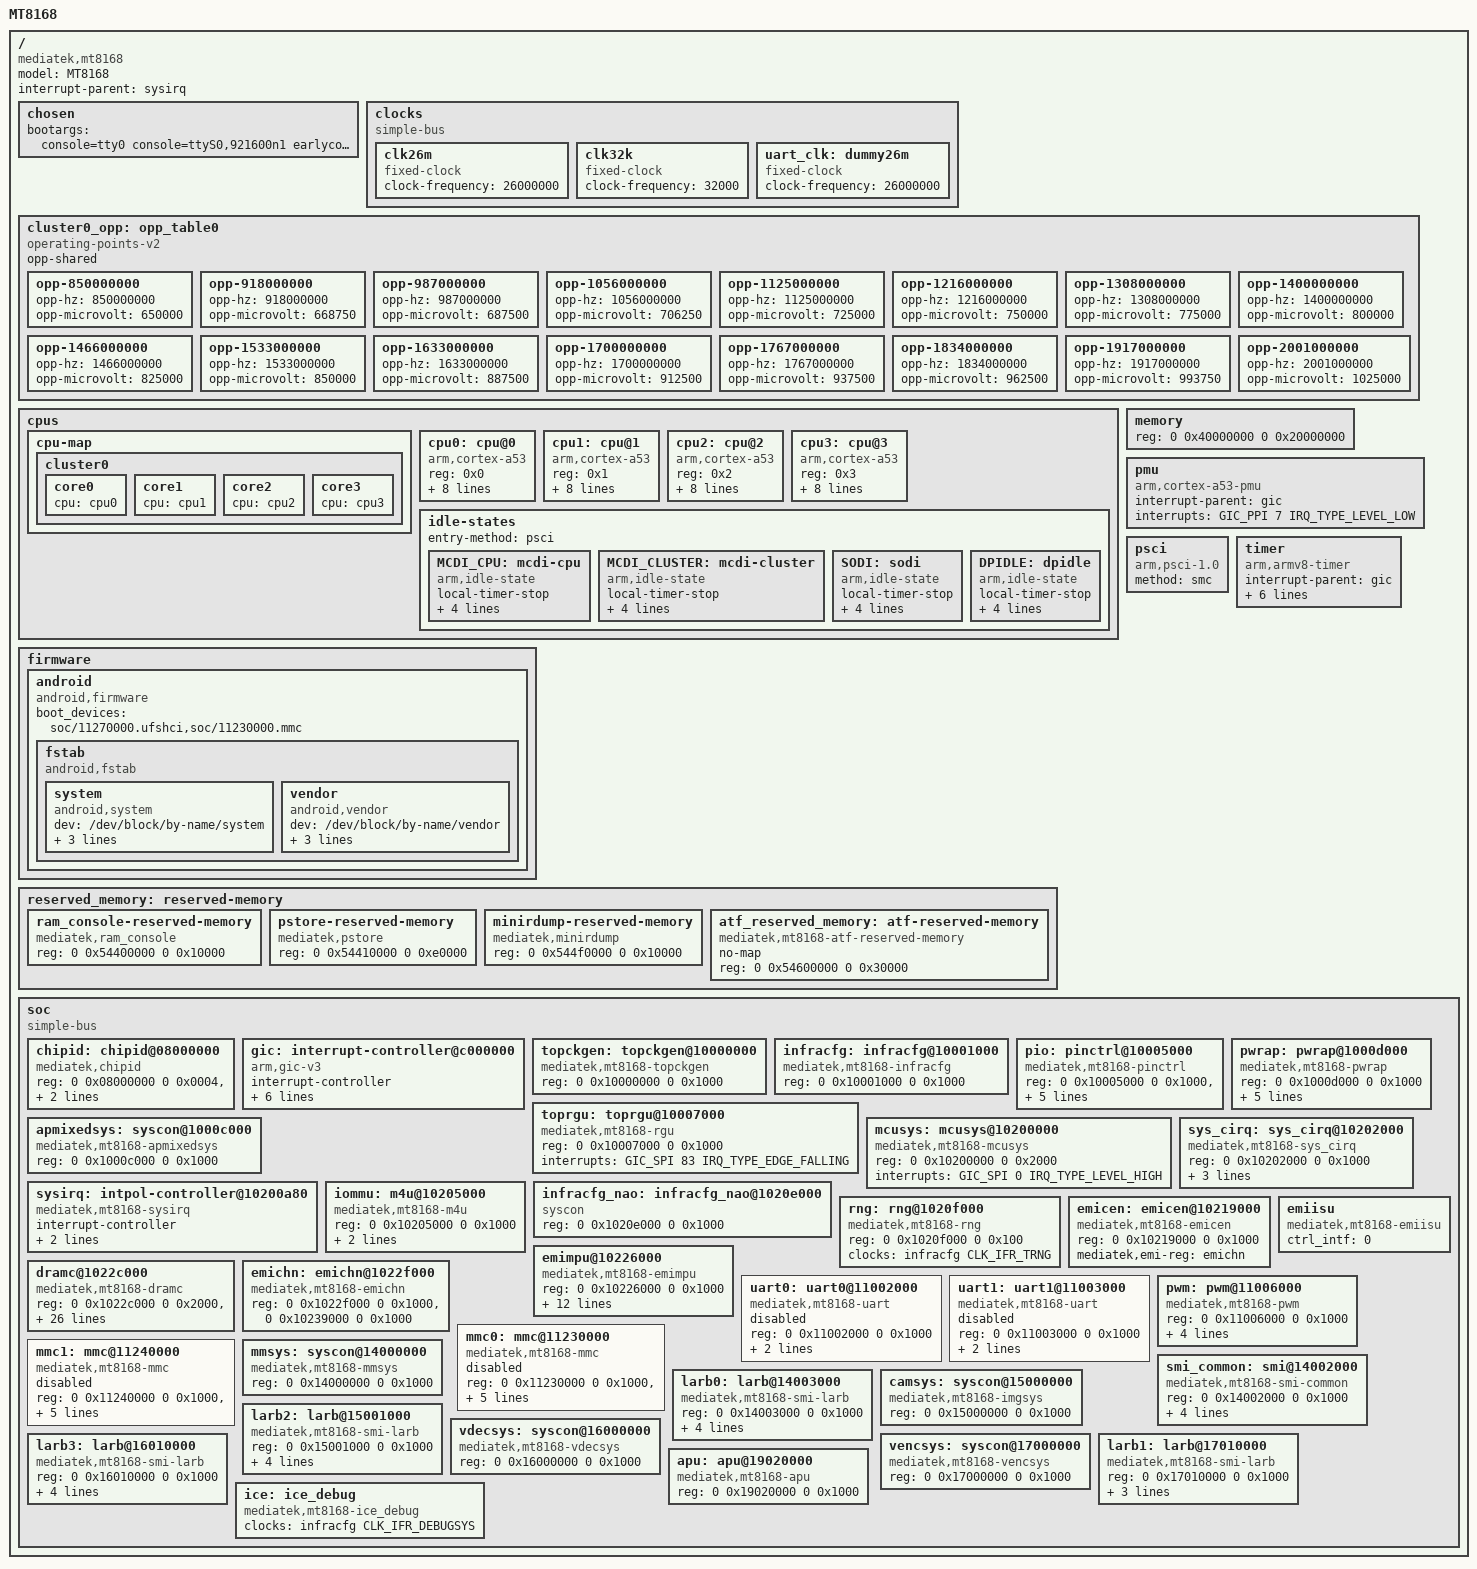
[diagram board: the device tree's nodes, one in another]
// SPDX-License-Identifier: GPL-2.0
/*
 * Mediatek's MT8168 SoC device tree source
 * Copyright (c) 2019 MediaTek Inc.
 */

#include <dt-bindings/clock/mt8168-clk.h>
#include <dt-bindings/iio/mt635x-auxadc.h>
#include <dt-bindings/interrupt-controller/irq.h>
#include <dt-bindings/interrupt-controller/arm-gic.h>
#include <dt-bindings/memory/mt8168-larb-port.h>
#include <dt-bindings/phy/phy.h>
#include <dt-bindings/pinctrl/mt8168-pinfunc.h>

/ {
	model = "MT8168";
	compatible = "mediatek,mt8168";
	interrupt-parent = <&sysirq>;
	#address-cells = <2>;
	#size-cells = <2>;

	/* chosen */
	chosen: chosen {
		bootargs = "console=tty0 console=ttyS0,921600n1 earlycon=uart8250,mmio32,0x11002000 vmalloc=496M androidboot.hardware=mt8168 firmware_class.path=/vendor/firmware loop.max_part=7";
	};

	clocks {
		#address-cells = <2>;
		#size-cells = <2>;
		compatible = "simple-bus";
		ranges;

		clk26m: clk26m {
			compatible = "fixed-clock";
			#clock-cells = <0>;
			clock-frequency = <26000000>;
		};

		clk32k: clk32k {
			compatible = "fixed-clock";
			#clock-cells = <0>;
			clock-frequency = <32000>;
		};

		uart_clk: dummy26m {
			compatible = "fixed-clock";
			clock-frequency = <26000000>;
			#clock-cells = <0>;
		};
	};

	cluster0_opp: opp_table0 {
		compatible = "operating-points-v2";
		opp-shared;
		opp-850000000 {
			opp-hz = /bits/ 64 <850000000>;
			opp-microvolt = <650000>;
		};
		opp-918000000 {
			opp-hz = /bits/ 64 <918000000>;
			opp-microvolt = <668750>;
		};
		opp-987000000 {
			opp-hz = /bits/ 64 <987000000>;
			opp-microvolt = <687500>;
		};
		opp-1056000000 {
			opp-hz = /bits/ 64 <1056000000>;
			opp-microvolt = <706250>;
		};
		opp-1125000000 {
			opp-hz = /bits/ 64 <1125000000>;
			opp-microvolt = <725000>;
		};
		opp-1216000000 {
			opp-hz = /bits/ 64 <1216000000>;
			opp-microvolt = <750000>;
		};
		opp-1308000000 {
			opp-hz = /bits/ 64 <1308000000>;
			opp-microvolt = <775000>;
		};
		opp-1400000000 {
			opp-hz = /bits/ 64 <1400000000>;
			opp-microvolt = <800000>;
		};
		opp-1466000000 {
			opp-hz = /bits/ 64 <1466000000>;
			opp-microvolt = <825000>;
		};
		opp-1533000000 {
			opp-hz = /bits/ 64 <1533000000>;
			opp-microvolt = <850000>;
		};
		opp-1633000000 {
			opp-hz = /bits/ 64 <1633000000>;
			opp-microvolt = <887500>;
		};
		opp-1700000000 {
			opp-hz = /bits/ 64 <1700000000>;
			opp-microvolt = <912500>;
		};
		opp-1767000000 {
			opp-hz = /bits/ 64 <1767000000>;
			opp-microvolt = <937500>;
		};
		opp-1834000000 {
			opp-hz = /bits/ 64 <1834000000>;
			opp-microvolt = <962500>;
		};
		opp-1917000000 {
			opp-hz = /bits/ 64 <1917000000>;
			opp-microvolt = <993750>;
		};
		opp-2001000000 {
			opp-hz = /bits/ 64 <2001000000>;
			opp-microvolt = <1025000>;
		};
	};

	cpus: cpus {
		#address-cells = <1>;
		#size-cells = <0>;

		cpu-map {
			cluster0: cluster0 {
				core0 {
					cpu = <&cpu0>;
				};
				core1 {
					cpu = <&cpu1>;
				};
				core2 {
					cpu = <&cpu2>;
				};
				core3 {
					cpu = <&cpu3>;
				};
			};
		};

		cpu0: cpu@0 {
			device_type = "cpu";
			compatible = "arm,cortex-a53";
			reg = <0x0>;
			clock-frequency = <1600000000>;
			enable-method = "psci";
			cpu-idle-states = <&MCDI_CPU &MCDI_CLUSTER &SODI
					   &DPIDLE>;
			clocks = <&mcusys CLK_MCU_BUS_SEL>,
				 <&apmixedsys CLK_APMIXED_MAINPLL>,
				 <&apmixedsys CLK_APMIXED_ARMPLL>;
			clock-names = "cpu", "intermediate", "armpll";
			operating-points-v2 = <&cluster0_opp>;
		};

		cpu1: cpu@1 {
			device_type = "cpu";
			compatible = "arm,cortex-a53";
			reg = <0x1>;
			clock-frequency = <1600000000>;
			enable-method = "psci";
			cpu-idle-states = <&MCDI_CPU &MCDI_CLUSTER &SODI
					   &DPIDLE>;
			clocks = <&mcusys CLK_MCU_BUS_SEL>,
				 <&apmixedsys CLK_APMIXED_MAINPLL>,
				 <&apmixedsys CLK_APMIXED_ARMPLL>;
			clock-names = "cpu", "intermediate", "armpll";
			operating-points-v2 = <&cluster0_opp>;
		};

		cpu2: cpu@2 {
			device_type = "cpu";
			compatible = "arm,cortex-a53";
			reg = <0x2>;
			clock-frequency = <1600000000>;
			enable-method = "psci";
			cpu-idle-states = <&MCDI_CPU &MCDI_CLUSTER &SODI
					   &DPIDLE>;
			clocks = <&mcusys CLK_MCU_BUS_SEL>,
				 <&apmixedsys CLK_APMIXED_MAINPLL>,
				 <&apmixedsys CLK_APMIXED_ARMPLL>;
			clock-names = "cpu", "intermediate", "armpll";
			operating-points-v2 = <&cluster0_opp>;
		};

		cpu3: cpu@3 {
			device_type = "cpu";
			compatible = "arm,cortex-a53";
			reg = <0x3>;
			clock-frequency = <1600000000>;
			enable-method = "psci";
			cpu-idle-states = <&MCDI_CPU &MCDI_CLUSTER &SODI
					   &DPIDLE>;
			clocks = <&mcusys CLK_MCU_BUS_SEL>,
				 <&apmixedsys CLK_APMIXED_MAINPLL>,
				 <&apmixedsys CLK_APMIXED_ARMPLL>;
			clock-names = "cpu", "intermediate", "armpll";
			operating-points-v2 = <&cluster0_opp>;
		};

		idle-states {
			entry-method = "psci";

			MCDI_CPU: mcdi-cpu {
				compatible = "arm,idle-state";
				local-timer-stop;
				arm,psci-suspend-param = <0x00010001>;
				entry-latency-us = <300>;
				exit-latency-us = <200>;
				min-residency-us = <1000>;
			};

			MCDI_CLUSTER: mcdi-cluster {
				compatible = "arm,idle-state";
				local-timer-stop;
				arm,psci-suspend-param = <0x01010001>;
				entry-latency-us = <350>;
				exit-latency-us = <250>;
				min-residency-us = <1200>;
			};

			SODI: sodi {
				compatible = "arm,idle-state";
				local-timer-stop;
				arm,psci-suspend-param = <0x01010002>;
				entry-latency-us = <300>;
				exit-latency-us = <850>;
				min-residency-us = <2300>;
			};

			DPIDLE: dpidle {
				compatible = "arm,idle-state";
				local-timer-stop;
				arm,psci-suspend-param = <0x01010004>;
				entry-latency-us = <350>;
				exit-latency-us = <1050>;
				min-residency-us = <2800>;
			};
		};
	};

	firmware {
		android {
			compatible = "android,firmware";
			boot_devices = "soc/11270000.ufshci,soc/11230000.mmc";
			fstab: fstab {
				compatible = "android,fstab";
				system {
					compatible = "android,system";
					dev = "/dev/block/by-name/system";
					type = "ext4";
					mnt_flags = "ro";
					fsmgr_flags = "wait";
				};
				vendor {
					compatible = "android,vendor";
					dev = "/dev/block/by-name/vendor";
					type = "ext4";
					mnt_flags = "ro";
					fsmgr_flags = "wait";
				};
			};
		};
	};

	memory {
		device_type = "memory";
		reg = <0 0x40000000 0 0x20000000>;
	};

	pmu {
		compatible = "arm,cortex-a53-pmu",
			     "arm,cortex-a7-pmu";
		interrupt-parent = <&gic>;
		interrupts = <GIC_PPI 7 IRQ_TYPE_LEVEL_LOW>;
	};

	psci {
		compatible      = "arm,psci-1.0";
		method          = "smc";
	};

	reserved_memory: reserved-memory {
		#address-cells = <2>;
		#size-cells = <2>;
		ranges;

		ram_console-reserved-memory {
			compatible = "mediatek,ram_console";
			reg = <0 0x54400000 0 0x10000>;
		};

		pstore-reserved-memory {
			compatible = "mediatek,pstore";
			reg = <0 0x54410000 0 0xe0000>;
		};

		minirdump-reserved-memory {
			compatible = "mediatek,minirdump";
			reg = <0 0x544f0000 0 0x10000>;
		};

		atf_reserved_memory: atf-reserved-memory {
			compatible = "mediatek,mt8168-atf-reserved-memory";
			no-map;
			reg = <0 0x54600000 0 0x30000>;
		};
	};

	timer: timer {
		compatible = "arm,armv8-timer";
		interrupt-parent = <&gic>;
		interrupts = <GIC_PPI 13
			     (GIC_CPU_MASK_SIMPLE(4) | IRQ_TYPE_LEVEL_LOW)>,
			     <GIC_PPI 14
			     (GIC_CPU_MASK_SIMPLE(4) | IRQ_TYPE_LEVEL_LOW)>,
			     <GIC_PPI 11
			     (GIC_CPU_MASK_SIMPLE(4) | IRQ_TYPE_LEVEL_LOW)>,
			     <GIC_PPI 10
			     (GIC_CPU_MASK_SIMPLE(4) | IRQ_TYPE_LEVEL_LOW)>;
		clock-frequency = <13000000>;
	};

	soc {
		#address-cells = <2>;
		#size-cells = <2>;
		compatible = "simple-bus";
		ranges;

		chipid: chipid@08000000 {
			compatible = "mediatek,chipid";
			reg = <0 0x08000000 0 0x0004>,
			      <0 0x08000004 0 0x0004>,
			      <0 0x08000008 0 0x0004>,
			      <0 0x0800000c 0 0x0004>;
		};

		gic: interrupt-controller@c000000 {
			compatible = "arm,gic-v3";
			interrupt-controller;
			#interrupt-cells = <3>;
			#address-cells = <2>;
			#size-cells = <2>;
			#redistributor-regions = <1>;
			interrupt-parent = <&gic>;
			reg = <0 0xc000000 0 0x80000>,
			      <0 0xc080000 0 0x80000>;
			interrupts = <GIC_PPI 9
				(GIC_CPU_MASK_SIMPLE(4) | IRQ_TYPE_LEVEL_HIGH)>;
		};

		topckgen: topckgen@10000000 {
			compatible = "mediatek,mt8168-topckgen", "syscon";
			reg = <0 0x10000000 0 0x1000>;
			#clock-cells = <1>;
		};

		infracfg: infracfg@10001000 {
			compatible = "mediatek,mt8168-infracfg", "syscon";
			reg = <0 0x10001000 0 0x1000>;
			#clock-cells = <1>;
		};

		pio: pinctrl@10005000 {
			compatible = "mediatek,mt8168-pinctrl";
			reg = <0 0x10005000 0 0x1000>,
			      <0 0x1000b000 0 0x1000>;
			reg-names = "iocfg0", "eint";
			gpio-controller;
			#gpio-cells = <2>;
			gpio-ranges = <&pio 0 0 144>;
			interrupt-controller;
			#interrupt-cells = <2>;
			interrupts = <GIC_SPI 115 IRQ_TYPE_LEVEL_HIGH>;
		};

		toprgu: toprgu@10007000 {
			compatible = "mediatek,mt8168-rgu",
				     "mediatek,mt6589-wdt";
			reg = <0 0x10007000 0 0x1000>;
			interrupts = <GIC_SPI 83 IRQ_TYPE_EDGE_FALLING>;
			#reset-cells = <1>;
		};

		apmixedsys: syscon@1000c000 {
			compatible = "mediatek,mt8168-apmixedsys", "syscon";
			reg = <0 0x1000c000 0 0x1000>;
			#clock-cells = <1>;
		};

		pwrap: pwrap@1000d000 {
			compatible = "mediatek,mt8168-pwrap";
			reg = <0 0x1000d000 0 0x1000>;
			reg-names = "pwrap";
			interrupts = <GIC_SPI 123 IRQ_TYPE_LEVEL_HIGH>;
			clocks = <&infracfg CLK_IFR_PWRAP_SPI>,
				 <&infracfg CLK_IFR_PMIC_AP>,
				 <&infracfg CLK_IFR_PWRAP_SYS>,
				 <&infracfg CLK_IFR_PWRAP_TMR>;
			clock-names = "spi", "wrap", "wrap_sys", "wrap_tmr";
		};

		mcusys: mcusys@10200000 {
			compatible = "mediatek,mt8168-mcusys",
				     "mediatek,mt8168-mcucfg", "syscon";
			reg = <0 0x10200000 0 0x2000>;
			interrupts = <GIC_SPI 0 IRQ_TYPE_LEVEL_HIGH>;
			#clock-cells = <1>;
		};

		sysirq: intpol-controller@10200a80 {
			compatible = "mediatek,mt8168-sysirq",
				     "mediatek,mt6577-sysirq";
			interrupt-controller;
			#interrupt-cells = <3>;
			interrupt-parent = <&gic>;
			reg = <0 0x10200a80 0 0x20>;
		};

		sys_cirq: sys_cirq@10202000 {
			compatible = "mediatek,mt8168-sys_cirq",
				     "mediatek,mt6735-sys_cirq",
				     "mediatek,sys_cirq";
			reg = <0 0x10202000 0 0x1000>;
			interrupts = <GIC_SPI 218 IRQ_TYPE_LEVEL_LOW>;
			mediatek,cirq_num = <147>;
			mediatek,spi_start_offset = <72>;
		};

		iommu: m4u@10205000 {
			compatible = "mediatek,mt8168-m4u";
			reg = <0 0x10205000 0 0x1000>;
			mediatek,larbs = <&larb0 &larb1 &larb2 &larb3>;
			interrupts = <GIC_SPI 102 IRQ_TYPE_LEVEL_LOW>;
			#iommu-cells = <1>;
		};

		infracfg_nao: infracfg_nao@1020e000 {
			compatible = "syscon";
			reg = <0 0x1020e000 0 0x1000>;
		};

		rng: rng@1020f000 {
			compatible = "mediatek,mt8168-rng",
				     "mediatek,mt7623-rng";
			reg = <0 0x1020f000 0 0x100>;
			clocks = <&infracfg CLK_IFR_TRNG>;
			clock-names = "rng";
		};

		emicen: emicen@10219000 {
			compatible = "mediatek,mt8168-emicen",
				     "mediatek,common-emicen";
			reg = <0 0x10219000 0 0x1000>;
			mediatek,emi-reg = <&emichn>;
		};

		emimpu@10226000 {
			compatible = "mediatek,mt8168-emimpu",
				     "mediatek,common-emimpu";
			reg = <0 0x10226000 0 0x1000>;
			mediatek,emi-reg = <&emicen>;
			interrupts = <GIC_SPI 88 IRQ_TYPE_LEVEL_LOW>;
			region_cnt = <16>;
			domain_cnt = <16>;
			addr_align = <16>;
			/* ap_region = <31>; */
			ap_apc = <5 5 5 5 5 5 5 5>,
					 <5 5 5 5 5 5 5 4>;
			dump = <0x1f0 0x1f8 0x1fc>;
			clear = <0x160 0xffffffff 16>,
					<0x200 0x00000003 16>,
					<0x1f0 0x80000000 1>;
			clear_md = <0x1fc 0x80000000 1>;
			ctrl_intf = <1>;
			slverr = <0>;
		};

		dramc@1022c000 {
			compatible = "mediatek,mt8168-dramc",
				     "mediatek,common-dramc";
			reg = <0 0x1022c000 0 0x2000>, /* DRAMC AO CHA */
				  <0 0x10232000 0 0x2000>, /* DRAMC AO CHB */
				  <0 0x1022e000 0 0x1000>, /* DRAMC NAO CHA */
				  <0 0x10238000 0 0x1000>, /* DRAMC NAO CHB */
				  <0 0x10228000 0 0x2000>, /* DDRPHY AO CHA */
				  <0 0x10234000 0 0x2000>, /* DDRPHY AO CHB */
				  <0 0x10230000 0 0x1000>, /* DDRPHY NAO CHA */
				  <0 0x1023a000 0 0x1000>, /* DDRPHY NAO CHB */
				  <0 0x10006000 0 0x1000>; /* SLEEP BASE */
			mr4_version = <1>;
			mr4_rg = <0x0090 0x0000ffff 0>;
			fmeter_version = <1>;
			crystal_freq = <52>;
			pll_id = <0x0510 0x80000000 31>;
			shu_lv = <0x00e4 0x00000006 1>;
			shu_of = <0x500>;
			sdmpcw = <0x0d9c 0xffff0000 16>,
					 <0x0d94 0xffff0000 16>;
			prediv = <0x0da8 0x000c0000 18>,
					 <0x0da0 0x000c0000 18>;
			posdiv = <0x0da8 0x00000007 0>,
					 <0x0da0 0x00000007 0>;
			ckdiv4 = <0x0d18 0x08000000 27>,
					 <0x0d18 0x08000000 27>;
			pll_md = <0x0d84 0x00000100 8>,
					 <0x0d84 0x00000100 8>;
			cldiv2 = <0x0c38 0x80000000 31>,
					 <0x0c38 0x80000000 31>;
		};

		emichn: emichn@1022f000 {
			compatible = "mediatek,mt8168-emichn",
				     "mediatek,common-emichn";
			reg = <0 0x1022f000 0 0x1000>,
				  <0 0x10239000 0 0x1000>;
		};

		emiisu {
			compatible = "mediatek,mt8168-emiisu",
				     "mediatek,common-emiisu";
			ctrl_intf = <0>;
		};

		uart0: uart0@11002000 {
			compatible = "mediatek,mt8168-uart",
				     "mediatek,mt6577-uart";
			reg = <0 0x11002000 0 0x1000>;
			interrupts = <GIC_SPI 35 IRQ_TYPE_LEVEL_LOW>;
			clocks = <&clk26m>, <&infracfg CLK_IFR_UART0>;
			clock-names = "baud", "bus";
			status = "disabled";
		};

		uart1: uart1@11003000 {
			compatible = "mediatek,mt8168-uart",
				     "mediatek,mt6577-uart";
			reg = <0 0x11003000 0 0x1000>;
			interrupts = <GIC_SPI 36 IRQ_TYPE_LEVEL_LOW>;
			clocks = <&clk26m>, <&infracfg CLK_IFR_UART1>;
			clock-names = "baud", "bus";
			status = "disabled";
		};

		pwm: pwm@11006000 {
			compatible = "mediatek,mt8168-pwm";
			reg = <0 0x11006000 0 0x1000>;
			interrupts = <GIC_SPI 76 IRQ_TYPE_LEVEL_LOW>;
			clocks = <&infracfg CLK_IFR_PWM_HCLK>,
				 <&infracfg CLK_IFR_PWM>,
				 <&infracfg CLK_IFR_PWM1>,
				 <&infracfg CLK_IFR_PWM2>,
				 <&infracfg CLK_IFR_PWM3>;
			clock-names = "top", "main", "pwm1", "pwm2", "pwm3";
		};

		mmc0: mmc@11230000 {
			compatible = "mediatek,mt8168-mmc";
			reg = <0 0x11230000 0 0x1000>,
			      <0 0x11cd0000 0 0x1000>;
			interrupts = <GIC_SPI 23 IRQ_TYPE_LEVEL_LOW>;
			clocks = <&topckgen CLK_TOP_MSDC50_0_SEL>,
				 <&infracfg CLK_IFR_MSDC0_HCLK>,
				 <&infracfg CLK_IFR_MSDC0_SRC>;
			clock-names = "source", "hclk", "source_cg";
			status = "disabled";
		};

		mmc1: mmc@11240000 {
			compatible = "mediatek,mt8168-mmc";
			reg = <0 0x11240000 0 0x1000>,
			      <0 0x11c90000 0 0x1000>;
			interrupts = <GIC_SPI 24 IRQ_TYPE_LEVEL_LOW>;
			clocks = <&topckgen CLK_TOP_MSDC30_1_SEL>,
				 <&infracfg CLK_IFR_MSDC1_HCLK>,
				 <&infracfg CLK_IFR_MSDC1_SRC>;
			clock-names = "source", "hclk", "source_cg";
			status = "disabled";
		};

		mmsys: syscon@14000000 {
			compatible = "mediatek,mt8168-mmsys", "syscon";
			reg = <0 0x14000000 0 0x1000>;
			#clock-cells = <1>;
		};

		smi_common: smi@14002000 {
			compatible = "mediatek,mt8168-smi-common", "syscon";
			reg = <0 0x14002000 0 0x1000>;
			clocks = <&mmsys CLK_MM_MM_SMI_COMMON>,
				 <&mmsys CLK_MM_MM_SMI_COMMON>,
				 <&mmsys CLK_MM_MM_SMI_COMM0>,
				 <&mmsys CLK_MM_MM_SMI_COMM1>;
			clock-names = "apb", "smi", "gals0", "gals1";
		};

		larb0: larb@14003000 {
			compatible = "mediatek,mt8168-smi-larb",
				     "mediatek,mt8183-smi-larb";
			reg = <0 0x14003000 0 0x1000>;
			mediatek,smi = <&smi_common>;
			mediatek,larb-id = <0>;
			clocks = <&mmsys CLK_MM_MM_SMI_LARB0>,
				 <&mmsys CLK_MM_MM_SMI_LARB0>;
			clock-names = "apb", "smi";
		};

		camsys: syscon@15000000 {
			compatible = "mediatek,mt8168-imgsys", "syscon";
			reg = <0 0x15000000 0 0x1000>;
			#clock-cells = <1>;
		};

		larb2: larb@15001000 {
			compatible = "mediatek,mt8168-smi-larb",
				     "mediatek,mt8183-smi-larb";
			reg = <0 0x15001000 0 0x1000>;
			mediatek,smi = <&smi_common>;
			mediatek,larb-id = <2>;
			clocks = <&mmsys CLK_MM_MM_SMI_IMG>,
				 <&camsys CLK_CAM_LARB2>;
			clock-names = "apb", "smi";
		};

		vdecsys: syscon@16000000 {
			compatible = "mediatek,mt8168-vdecsys", "syscon";
			reg = <0 0x16000000 0 0x1000>;
			#clock-cells = <1>;
		};

		larb3: larb@16010000 {
			compatible = "mediatek,mt8168-smi-larb",
				     "mediatek,mt8183-smi-larb";
			reg = <0 0x16010000 0 0x1000>;
			mediatek,smi = <&smi_common>;
			mediatek,larb-id = <3>;
			clocks = <&vdecsys CLK_VDEC_LARB1>,
				 <&vdecsys CLK_VDEC_LARB1>;
			clock-names = "apb", "smi";
		};

		vencsys: syscon@17000000 {
			compatible = "mediatek,mt8168-vencsys", "syscon";
			reg = <0 0x17000000 0 0x1000>;
			#clock-cells = <1>;
		};

		larb1: larb@17010000 {
			compatible = "mediatek,mt8168-smi-larb",
				     "mediatek,mt8183-smi-larb";
			reg = <0 0x17010000 0 0x1000>;
			mediatek,smi = <&smi_common>;
			mediatek,larb-id = <1>;
			clocks = <&vencsys CLK_VENC>, <&vencsys CLK_VENC>;
			clock-names = "apb", "smi";
		};

		apu: apu@19020000 {
			compatible = "mediatek,mt8168-apu", "syscon";
			reg = <0 0x19020000 0 0x1000>;
			#clock-cells = <1>;
		};

		ice: ice_debug {
			compatible = "mediatek,mt8168-ice_debug",
				     "mediatek,mt2701-ice_debug";
			clocks = <&infracfg CLK_IFR_DEBUGSYS>;
			clock-names = "ice_dbg";
		};
	};
};
